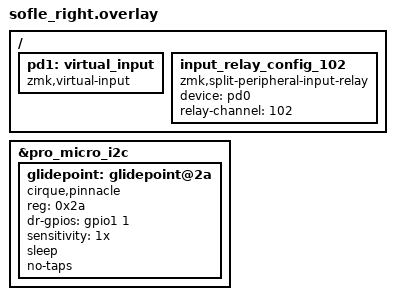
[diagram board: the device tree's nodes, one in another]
#include "sofle.dtsi"


/* enable &pd0 on split peripheral. typical input device for zephyr input subsystem. */
/* NOTE 1: use the same device alias (&pd0) on central and peripheral(s) is alright. */
/* NOTE 2: input event shall be intecepted by module `zmk-split-peripheral-input-relay`. */

/* this is an alias of your actual wired input device sensor in your peripheral shield. */
/* e.g. SPI optical sensor for trackball */
&pro_micro_i2c {
    status = "okay";
    glidepoint: glidepoint@2a {
        compatible = "cirque,pinnacle";
        reg = <0x2a>;
        status = "okay";
        dr-gpios = <&gpio1 1 (GPIO_ACTIVE_HIGH)>;

        sensitivity = "1x";
        sleep;
        no-taps;
    };
};

/ {
	/* THIS make keymap binding happy only, nothing happen on peripheral side */
	pd1: virtual_input {
		compatible = "zmk,virtual-input";
	};

	/* for peripheral side, define (input-device)-to-(relay-channel) mapping */
	input_relay_config_102 {
		compatible = "zmk,split-peripheral-input-relay";

		/* peripheral side input device, used to... */
		/*  - be intecepted on peripheral; */
		/*  - and then, be resurrected as `zmk,virtual-device` on central; */
		device = <&pd0>;
		
		/* channel id, used to be be transfered along with all input events. */
		/* NOTE 1: pick any 8bit integer. (1 - 255) */
		/* NOTE 2: should matching relay-channel on central overlay */
		relay-channel = <102>;
	};
};
